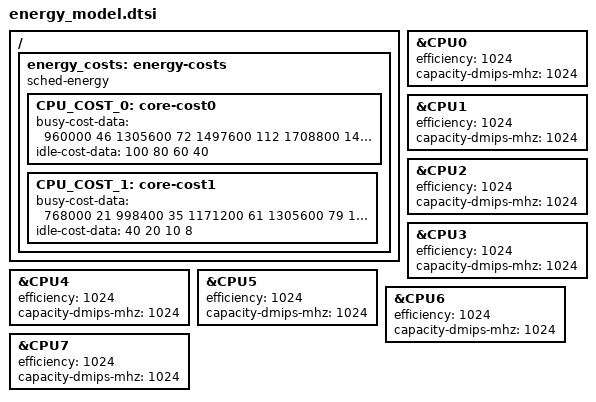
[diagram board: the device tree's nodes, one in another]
&CPU0 {
         efficiency = <1024>;
         capacity-dmips-mhz = <1024>;
};

&CPU1 {
         efficiency = <1024>;
         capacity-dmips-mhz = <1024>;
};

&CPU2 {
         efficiency = <1024>;
         capacity-dmips-mhz = <1024>;
};

&CPU3 {
        efficiency = <1024>;
        capacity-dmips-mhz = <1024>;
};

&CPU4 {
        efficiency = <1024>;
        capacity-dmips-mhz = <1024>;
};

&CPU5 {
        efficiency = <1024>;
        capacity-dmips-mhz = <1024>;
};

&CPU6 {
        efficiency = <1024>;
        capacity-dmips-mhz = <1024>;
};

&CPU7 {
        efficiency = <1024>;
        capacity-dmips-mhz = <1024>;
};

/ {
        /delete-node/ energy-costs;
        energy_costs: energy-costs {
                compatible = "sched-energy";

                CPU_COST_0: core-cost0 {
                        busy-cost-data = <
                                  960000   46
                                 1305600   72
                                 1497600  112
                                 1708800  144
                                 1958400  221
                                 2016000  227
                        >;
                        idle-cost-data = <
                                100 80 60 40
                        >;
                };

                CPU_COST_1: core-cost1 {
                        busy-cost-data = <
                                  768000   21
                                  998400   35
                                 1171200   61
                                 1305600   79
                                 1459200  112
                        >;
			idle-cost-data = <
				40 20 10 8
			>;
                };
        };
};
